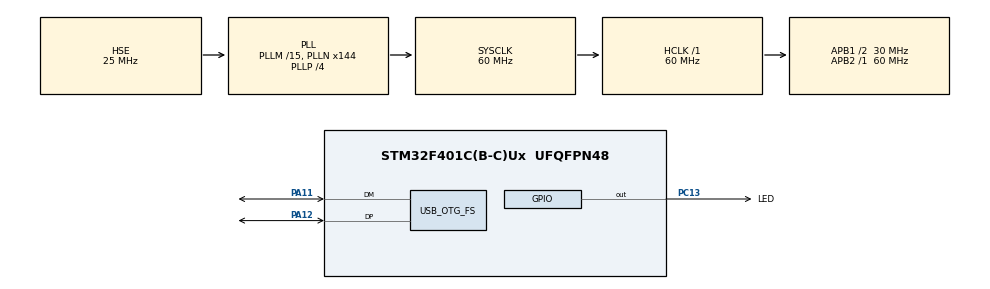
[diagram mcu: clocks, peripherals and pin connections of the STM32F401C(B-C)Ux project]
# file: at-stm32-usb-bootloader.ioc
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Mcu.Family=STM32F4
Mcu.Name=STM32F401C(B-C)Ux
Mcu.Package=UFQFPN48
NVIC.OTG_FS_IRQn=true\:0\:0\:false\:false\:true\:true\:true
NVIC.PriorityGroup=NVIC_PRIORITYGROUP_4
NVIC.TIM4_IRQn=true\:0\:0\:false\:false\:true\:true\:true
PA11.Mode=Device_Only
PA11.Signal=USB_OTG_FS_DM
PA12.Mode=Device_Only
PA12.Signal=USB_OTG_FS_DP
PC13-ANTI_TAMP.GPIO_Label=LED
PC13-ANTI_TAMP.Signal=GPIO_Output
PC14-OSC32_IN.Mode=LSE-External-Oscillator
PC14-OSC32_IN.Signal=RCC_OSC32_IN
PC15-OSC32_OUT.Mode=LSE-External-Oscillator
PC15-OSC32_OUT.Signal=RCC_OSC32_OUT
PH0\ -\ OSC_IN.Mode=HSE-External-Oscillator
PH0\ -\ OSC_IN.Signal=RCC_OSC_IN
PH1\ -\ OSC_OUT.Mode=HSE-External-Oscillator
PH1\ -\ OSC_OUT.Signal=RCC_OSC_OUT
ProjectManager.HeapSize=0x200
ProjectManager.StackSize=0x400
ProjectManager.TargetToolchain=SW4STM32
RCC.48MHZClocksFreq_Value=48000000
RCC.AHBFreq_Value=60000000
RCC.APB1CLKDivider=RCC_HCLK_DIV2
RCC.APB1Freq_Value=30000000
RCC.APB1TimFreq_Value=60000000
RCC.APB2Freq_Value=60000000
RCC.APB2TimFreq_Value=60000000
RCC.CortexFreq_Value=60000000
RCC.HCLKFreq_Value=60000000
RCC.HSE_VALUE=25000000
RCC.HSI_VALUE=16000000
RCC.PLLM=15
RCC.PLLN=144
RCC.PLLP=RCC_PLLP_DIV4
RCC.PLLQ=5
RCC.SYSCLKFreq_VALUE=60000000
RCC.SYSCLKSource=RCC_SYSCLKSOURCE_PLLCLK
RCC.VCOOutputFreq_Value=240000000
TIM4.Period=8400-1
TIM4.Prescaler=100-1
USB_DEVICE.CLASS_NAME_FS=MSC
USB_DEVICE.VirtualMode=Msc
USB_DEVICE.VirtualModeFS=Msc_FS
USB_OTG_FS.VirtualMode=Device_Only
VP_TIM4_VS_ClockSourceINT.Mode=Internal
VP_USB_DEVICE_VS_USB_DEVICE_MSC_FS.Mode=MSC_FS
board=custom

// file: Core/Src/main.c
/* USER CODE BEGIN Header */
/*
 * Copyright (c) Alex2772, https://github.com/alex2772
 *
 * This program is free software: you can redistribute it and/or modify
 * it under the terms of the GNU General Public License as published by
 * the Free Software Foundation, either version 3 of the License, or
 * (at your option) any later version.
 *
 * This program is distributed in the hope that it will be useful,
 * but WITHOUT ANY WARRANTY; without even the implied warranty of
 * MERCHANTABILITY or FITNESS FOR A PARTICULAR PURPOSE.  See the
 * GNU General Public License for more details.
 *
 * You should have received a copy of the GNU General Public License
 * along with this program.  If not, see <http://www.gnu.org/licenses/>.
 */

/* USER CODE END Header */
#include "main.h"
#include "usb_device.h"

TIM_HandleTypeDef htim4;

void SystemClock_Config(void);
static void MX_GPIO_Init(void);
static void MX_TIM4_Init(void);

int main(void)
{

  /* MCU Configuration--------------------------------------------------------*/

  /* Reset of all peripherals, Initializes the Flash interface and the Systick. */
  HAL_Init();

  /* Configure the system clock */
  SystemClock_Config();

  /* Initialize all configured peripherals */
  MX_GPIO_Init();
  MX_TIM4_Init();
  MX_USB_DEVICE_Init();

  /* Infinite loop */
  while (1)
  {

  }
}

void SystemClock_Config(void)
{
  RCC_OscInitTypeDef RCC_OscInitStruct = {0};
  RCC_ClkInitTypeDef RCC_ClkInitStruct = {0};

  /** Configure the main internal regulator output voltage
  */
  __HAL_RCC_PWR_CLK_ENABLE();
  __HAL_PWR_VOLTAGESCALING_CONFIG(PWR_REGULATOR_VOLTAGE_SCALE2);
  /** Initializes the RCC Oscillators according to the specified parameters
  * in the RCC_OscInitTypeDef structure.
  */
  RCC_OscInitStruct.OscillatorType = RCC_OSCILLATORTYPE_HSE;
  RCC_OscInitStruct.HSEState = RCC_HSE_ON;
  RCC_OscInitStruct.PLL.PLLState = RCC_PLL_ON;
  RCC_OscInitStruct.PLL.PLLSource = RCC_PLLSOURCE_HSE;
  RCC_OscInitStruct.PLL.PLLM = 15;
  RCC_OscInitStruct.PLL.PLLN = 144;
  RCC_OscInitStruct.PLL.PLLP = RCC_PLLP_DIV4;
  RCC_OscInitStruct.PLL.PLLQ = 5;
  if (HAL_RCC_OscConfig(&RCC_OscInitStruct) != HAL_OK)
  {
    Error_Handler();
  }
  /** Initializes the CPU, AHB and APB buses clocks
  */
  RCC_ClkInitStruct.ClockType = RCC_CLOCKTYPE_HCLK|RCC_CLOCKTYPE_SYSCLK
                              |RCC_CLOCKTYPE_PCLK1|RCC_CLOCKTYPE_PCLK2;
  RCC_ClkInitStruct.SYSCLKSource = RCC_SYSCLKSOURCE_PLLCLK;
  RCC_ClkInitStruct.AHBCLKDivider = RCC_SYSCLK_DIV1;
  RCC_ClkInitStruct.APB1CLKDivider = RCC_HCLK_DIV2;
  RCC_ClkInitStruct.APB2CLKDivider = RCC_HCLK_DIV1;

  if (HAL_RCC_ClockConfig(&RCC_ClkInitStruct, FLASH_LATENCY_1) != HAL_OK)
  {
    Error_Handler();
  }
}

static void MX_TIM4_Init(void)
{

  TIM_ClockConfigTypeDef sClockSourceConfig = {0};
  TIM_MasterConfigTypeDef sMasterConfig = {0};

  htim4.Instance = TIM4;
  htim4.Init.Prescaler = 100-1;
  htim4.Init.CounterMode = TIM_COUNTERMODE_UP;
  htim4.Init.Period = 8400-1;
  htim4.Init.ClockDivision = TIM_CLOCKDIVISION_DIV1;
  htim4.Init.AutoReloadPreload = TIM_AUTORELOAD_PRELOAD_DISABLE;
  if (HAL_TIM_Base_Init(&htim4) != HAL_OK)
  {
    Error_Handler();
  }
  sClockSourceConfig.ClockSource = TIM_CLOCKSOURCE_INTERNAL;
  if (HAL_TIM_ConfigClockSource(&htim4, &sClockSourceConfig) != HAL_OK)
  {
    Error_Handler();
  }
  sMasterConfig.MasterOutputTrigger = TIM_TRGO_RESET;
  sMasterConfig.MasterSlaveMode = TIM_MASTERSLAVEMODE_DISABLE;
  if (HAL_TIMEx_MasterConfigSynchronization(&htim4, &sMasterConfig) != HAL_OK)
  {
    Error_Handler();
  }

}

static void MX_GPIO_Init(void)
{
  GPIO_InitTypeDef GPIO_InitStruct = {0};

  /* GPIO Ports Clock Enable */
  __HAL_RCC_GPIOC_CLK_ENABLE();
  __HAL_RCC_GPIOH_CLK_ENABLE();
  __HAL_RCC_GPIOA_CLK_ENABLE();

  /*Configure GPIO pin Output Level */
  HAL_GPIO_WritePin(LED_GPIO_Port, LED_Pin, GPIO_PIN_RESET);

  /*Configure GPIO pin : LED_Pin */
  GPIO_InitStruct.Pin = LED_Pin;
  GPIO_InitStruct.Mode = GPIO_MODE_OUTPUT_PP;
  GPIO_InitStruct.Pull = GPIO_NOPULL;
  GPIO_InitStruct.Speed = GPIO_SPEED_FREQ_LOW;
  HAL_GPIO_Init(LED_GPIO_Port, &GPIO_InitStruct);

}

void Error_Handler(void)
{
  /* USER CODE BEGIN Error_Handler_Debug */
  /* User can add his own implementation to report the HAL error return state */
  __disable_irq();
  while (1)
  {
      HAL_NVIC_SystemReset();
  }
  /* USER CODE END Error_Handler_Debug */
}

/************************ (C) COPYRIGHT STMicroelectronics *****END OF FILE****/
